# SAM3N2A register map
File version: 0
Registers are 32-bit, read-write, reset 0x0 unless marked. A register's access mark holds for its fields unless they carry their own. Offsets are from the block's base; [hi:lo] are bit positions; {n}, {i} and the like mark numbered series.

## ADC — Analog-to-digital Converter
Base 0x40038000; register names take the prefix ADC_
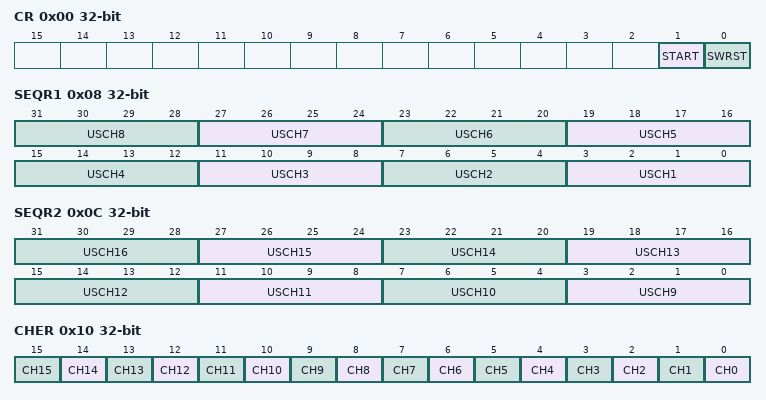
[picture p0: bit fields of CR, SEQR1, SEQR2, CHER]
0x00 CR wo reset not defined — Control Register
  [1] START — Start Conversion
  [0] SWRST — Software Reset
0x04 MR — Mode Register
0x08 SEQR1 — Channel Sequence Register 1
  [4n-1:4n-4] USCH{n} (n=1..8) — User Sequence Number {n}
0x0C SEQR2 — Channel Sequence Register 2
  [4n-33:4n-36] USCH{n} (n=9..16) — User Sequence Number {n}
0x10 CHER wo reset not defined — Channel Enable Register
  [n] CH{n} (n=0..15) — Channel {n} Enable
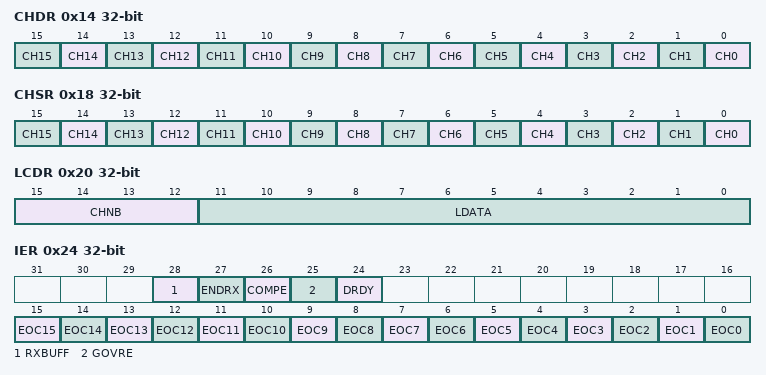
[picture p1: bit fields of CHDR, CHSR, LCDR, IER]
0x14 CHDR wo reset not defined — Channel Disable Register
  [n] CH{n} (n=0..15) — Channel {n} Disable
0x18 CHSR ro — Channel Status Register
  [n] CH{n} (n=0..15) — Channel {n} Status
0x20 LCDR ro — Last Converted Data Register
  [15:12] CHNB — Channel Number
  [11:0] LDATA — Last Data Converted
0x24 IER wo reset not defined — Interrupt Enable Register
  [28] RXBUFF — Receive Buffer Full Interrupt Enable
  [27] ENDRX — End of Receive Buffer Interrupt Enable
  [26] COMPE — Comparison Event Interrupt Enable
  [25] GOVRE — General Overrun Error Interrupt Enable
  [24] DRDY — Data Ready Interrupt Enable
  [n] EOC{n} (n=0..15) — End of Conversion Interrupt Enable {n}
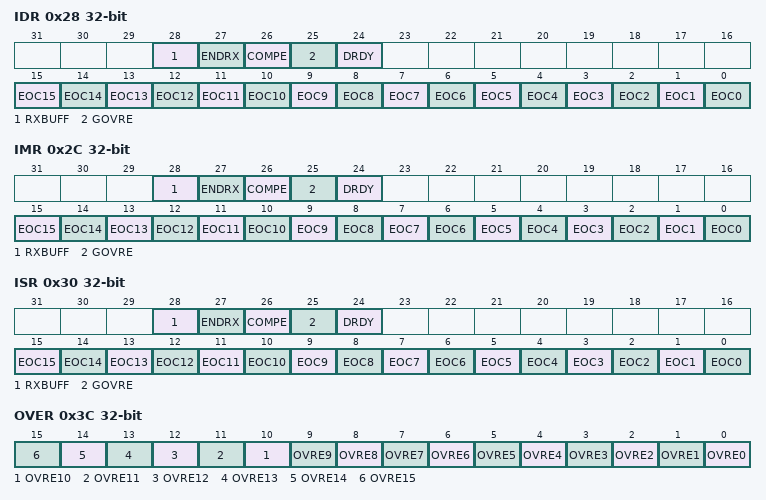
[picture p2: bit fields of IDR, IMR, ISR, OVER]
0x28 IDR wo reset not defined — Interrupt Disable Register
  [28] RXBUFF — Receive Buffer Full Interrupt Disable
  [27] ENDRX — End of Receive Buffer Interrupt Disable
  [26] COMPE — Comparison Event Interrupt Disable
  [25] GOVRE — General Overrun Error Interrupt Disable
  [24] DRDY — Data Ready Interrupt Disable
  [n] EOC{n} (n=0..15) — End of Conversion Interrupt Disable {n}
0x2C IMR ro — Interrupt Mask Register
  [28] RXBUFF — Receive Buffer Full Interrupt Mask
  [27] ENDRX — End of Receive Buffer Interrupt Mask
  [26] COMPE — Comparison Event Interrupt Mask
  [25] GOVRE — General Overrun Error Interrupt Mask
  [24] DRDY — Data Ready Interrupt Mask
  [n] EOC{n} (n=0..15) — End of Conversion Interrupt Mask {n}
0x30 ISR ro — Interrupt Status Register
  [28] RXBUFF — RX Buffer Full
  [27] ENDRX — End of RX Buffer
  [26] COMPE — Comparison Error
  [25] GOVRE — General Overrun Error
  [24] DRDY — Data Ready
  [n] EOC{n} (n=0..15) — End of Conversion {n}
0x3C OVER ro — Overrun Status Register
  [n] OVRE{n} (n=0..15) — Overrun Error {n}
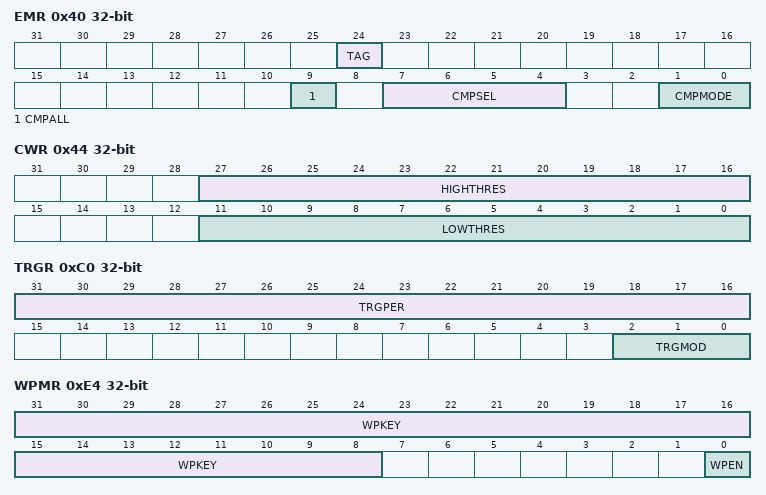
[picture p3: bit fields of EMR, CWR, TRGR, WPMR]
0x40 EMR — Extended Mode Register
  [24] TAG — TAG of ADC_LDCR register
  [9] CMPALL — Compare All Channels
  [7:4] CMPSEL — Comparison Selected Channel
  [1:0] CMPMODE — Comparison Mode
    0=LOW (Generates an event when the converted data is lower than the low threshold of the window.); 1=HIGH (Generates an event when the converted data is higher than the high threshold of the window.); 2=IN (Generates an event when the converted data is in the comparison window.); 3=OUT (Generates an event when the converted data is out of the comparison window.)
0x44 CWR — Compare Window Register
  [27:16] HIGHTHRES — High Threshold
  [11:0] LOWTHRES — Low Threshold
{0x50+4i} CDR{i} (i=0..15) ro reset not defined — Channel Data Register
  [11:0] DATA — Converted Data
0xC0 TRGR — Trigger Register
  [31:16] TRGPER — Trigger Period
  [2:0] TRGMOD — Trigger Mode
    0=NO_TRIGGER (No trigger, only software trigger can start conversions); 1=EXT_TRIG_RISE (External Trigger Rising Edge); 2=EXT_TRIG_FALL (External Trigger Falling Edge); 3=EXT_TRIG_ANY (External Trigger Any Edge); 5=PERIOD_TRIG (Periodic Trigger (TRGPER shall be initiated appropriately)); 6=CONTINUOUS (Continuous Mode)
0xE4 WPMR — Write Protect Mode Register
  [31:8] WPKEY — Write Protect KEY
  [0] WPEN — Write Protect Enable
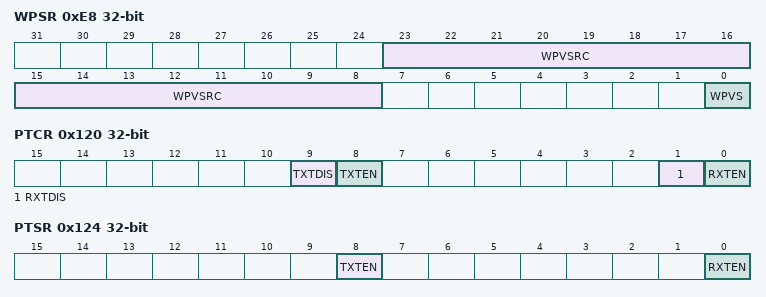
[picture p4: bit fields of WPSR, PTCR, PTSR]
0xE8 WPSR ro — Write Protect Status Register
  [23:8] WPVSRC — Write Protect Violation Source
  [0] WPVS — Write Protect Violation Status
0x100 RPR — Receive Pointer Register
  [31:0] RXPTR
0x104 RCR — Receive Counter Register
  [15:0] RXCTR
0x108 TPR — Transmit Pointer Register
  [31:0] TXPTR — Transmit Counter Register
0x10C TCR — Transmit Counter Register
  [15:0] TXCTR
0x110 RNPR — Receive Next Pointer Register
  [31:0] RXNPTR — Receive Next Pointer
0x114 RNCR — Receive Next Counter Register
  [15:0] RXNCTR — Receive Next Counter
0x118 TNPR — Transmit Next Pointer Register
  [31:0] TXNPTR — Transmit Next Pointer
0x11C TNCR — Transmit Next Counter Register
  [15:0] TXNCTR — Transmit Counter Next
0x120 PTCR wo — Transfer Control Register
  [9] TXTDIS — Transmitter Transfer Disable
  [8] TXTEN — Transmitter Transfer Enable
  [1] RXTDIS — Receiver Transfer Disable
  [0] RXTEN — Receiver Transfer Enable
0x124 PTSR ro — Transfer Status Register
  [8] TXTEN — Transmitter Transfer Enable
  [0] RXTEN — Receiver Transfer Enable

## Notices in the file
Copyright (c) 2011, Atmel Corporation
All rights reserved.
Redistribution and use in source and binary forms, with or without
modification, are permitted provided that the following condition is met:
- Redistributions of source code must retain the above copyright notice,
this list of conditions and the disclaimer below.
Atmel's name may not be used to endorse or promote products derived from
this software without specific prior written permission.
DISCLAIMER:  THIS SOFTWARE IS PROVIDED BY ATMEL "AS IS" AND ANY EXPRESS OR
IMPLIED WARRANTIES, INCLUDING, BUT NOT LIMITED TO, THE IMPLIED WARRANTIES OF
MERCHANTABILITY, FITNESS FOR A PARTICULAR PURPOSE AND NON-INFRINGEMENT ARE
DISCLAIMED. IN NO EVENT SHALL ATMEL BE LIABLE FOR ANY DIRECT, INDIRECT,
INCIDENTAL, SPECIAL, EXEMPLARY, OR CONSEQUENTIAL DAMAGES (INCLUDING, BUT NOT
LIMITED TO, PROCUREMENT OF SUBSTITUTE GOODS OR SERVICES; LOSS OF USE, DATA,
OR PROFITS; OR BUSINESS INTERRUPTION) HOWEVER CAUSED AND ON ANY THEORY OF
LIABILITY, WHETHER IN CONTRACT, STRICT LIABILITY, OR TORT (INCLUDING
NEGLIGENCE OR OTHERWISE) ARISING IN ANY WAY OUT OF THE USE OF THIS SOFTWARE,
EVEN IF ADVISED OF THE POSSIBILITY OF SUCH DAMAGE.
